# LKS32MC07x register map
Vendor: Linko Ltd.; Series: LKS32MC07x; File version: 1.0
CPU: CM0 r1p0, little endian, MPU, no FPU, 3 interrupt priority bits
Registers are 32-bit, read-write, reset 0x0 unless marked. A register's access mark holds for its fields unless they carry their own. Offsets are from the block's base; [hi:lo] are bit positions; {n}, {i} and the like mark numbered series.

## CAN0 — CAN0 registers
Base 0x40011300
{0x0+4i} RBUF{i} ro (i=0..3) — Receive Buffer register
  [31:0] RDATA — CAN frame date from Rx Buffer Slot
{0x50+4i} TBUF{i} wo (i=0..3) — Transmit Buffer register
  [31:0] WDATA — CAN frame ic written into TX Buffer Slot(PTB or STB)
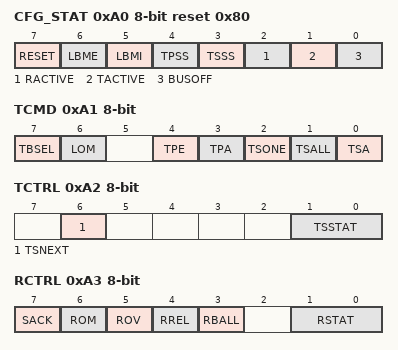
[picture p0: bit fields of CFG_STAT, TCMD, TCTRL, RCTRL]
0xA0 CFG_STAT 8-bit reset 0x80 — Configuration and Status Register
  [7] RESET — RESET request bit
    0=RELEASE (normail mode); 1=RESET (reset mode)
  [6] LBME — Loop Back Mode, External
    0=DISABLED (disable external loop back mode); 1=ENABLED (enable external loop back mode)
  [5] LBMI — Loop Back Mode, Internal
    0=DISABLED (disable internal loop back mode); 1=ENABLED (enable internal loop back mode)
  [4] TPSS — Transmission Primary Single Shot mode for PTB
    0=DISABLED (disable transmission Primary Single Shot mode for PTB); 1=ENABLED (enable transmission Primary Single Shot mode for PTB)
  [3] TSSS — Transmission Secondary Single Shot mode for STB
    0=DISABLED (disable transmission Primary Single Shot mode for STB); 1=ENABLED (enable transmission Primary Single Shot mode for STB)
  [2] RACTIVE ro — Reception ACTIVE
    0=DISABLED (receive idle,bus idle); 1=ENABLED (device is receiving CAN frame)
  [1] TACTIVE ro — Transmission ACTIVE
    0=DISABLED (transimit idle); 1=ENABLED (device is transimitting CAN frame)
  [0] BUSOFF — Bus Off (Bus Status bit)
    0=DISABLED (device is in bus off); 1=DISABLED (device is not in bus off)
0xA1 TCMD 8-bit — Command Register
  [7] TBSEL — Transmit Buffer Select
    0=PTB; 1=STB
  [6] LOM — Listen Only Mode
    0=DISABLED; 1=ENABLED
  [4] TPE ro — Transmit Primary Enable
    0=DISABLED (disable trigger PTB transmit); 1=ENABLED (trigger PTB transmit)
  [3] TPA ro — Transmit Primary Abort
    0=DISABLED; 1=ENABLED
  [2] TSONE ro — Transmit Secondary ONE frame
    0=DISABLED; 1=ENABLED
  [1] TSALL ro — Transmit Secondary ALL frames
    0=DISABLED; 1=ENABLED
  [0] TSA ro — Transmit Secondary Abort
    0=DISABLED; 1=ENABLED
0xA2 TCTRL 8-bit — Transmit Control Register
  [6] TSNEXT — Transmit buffer Secondary NEXT
  [1:0] TSSTAT — Transmission Secondary STATus bits
    0=EMPTY (STB is empty); 1=LTHF (STB is less than or equal to half full); 2=MTHF (STB is more than half full); 3=FULL (STB is full)
0xA3 RCTRL 8-bit — Receive Control Register
  [7] SACK — Self-ACKnowledge
    0=DISABLED (no self-ACK); 1=ENABLED (self-ACK when LBME=1)
  [6] ROM — Receive buffer Overflow Mode
    0=DISABLED (The oldest message will be overwritten); 1=ENABLED (The new message will not be stored)
  [5] ROV ro — Receive buffer Overflow
    0=NOOVFL (No Overflow); 1=OVFL (Overflow. At least one message is lost)
  [4] RREL — Receive buffer RELease
    0=NORELEASE; 1=RELEASE (Release: The host has read the RB)
  [3] RBALL — Receive Buffer stores ALL data frames
    0=DISABLED (normal operation); 1=ENABLED (RB stores correct data frames as well as data frames with error)
  [1:0] RSTAT ro — Receive buffer Status
    0=EMPTY; 1=NOTEMPTY (not empty and less then almost full); 2=ALMOSTFULL (almost full but not full and no overflow); 3=FULL (full, stays set in case of overflow - for overflow signaling see ROV)
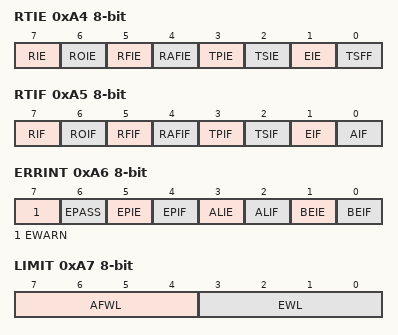
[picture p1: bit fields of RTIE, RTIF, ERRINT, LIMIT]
0xA4 RTIE 8-bit — Receive and Transmit Interrupt Enable Register
  [all] fields
    0=DISABLED; 1=ENABLED
  [7] RIE — Receive Interrupt Enable
  [6] ROIE — RX Buffer Overrun Interrupt Enable
  [5] RFIE — RX Buffer Full Interrupt Interrupt Enable
  [4] RAFIE — RB Almost Full Interrupt Enable
  [3] TPIE — Transmission Primary Interrupt Enable
  [2] TSIE — Transmission Secondary Interrupt Enable
  [1] EIE — Error Interrupt Enable
  [0] TSFF — Tx Buffer Flag
0xA5 RTIF 8-bit — Receive and Transmit Interrupt Flag Register
  [all] fields
    0=CLEAR; 1=SET
  [7] RIF — Receive Interrupt Flag
  [6] ROIF — RB Overrun Interrupt Flag
  [5] RFIF — RB Full Interrupt Flag
  [4] RAFIF — RB Almost Full Interrupt Flag
  [3] TPIF — Transmission Primary Interrupt Flag
  [2] TSIF — Transmission Secondary Interrupt Flag
  [1] EIF — Error Interrupt Flag
  [0] AIF — Abort Interrupt Flag
0xA6 ERRINT 8-bit — Error Interrupt Enable and Flag Register
  [7] EWARN — Error WARNing limit reached
    0=NOTREACH; 1=REACHED
  [6] EPASS ro — Error Passive mode active
    0=ERRACTIVE (CAN is in active error status); 1=ERRPASSIVE (CAN is in passive error status)
  [5] EPIE — Error Passive Interrupt Enable
    0=DISABLED (Error passive interrupt disable); 1=ENABLED (Error passive interrupt enable)
  [4] EPIF — Error Passive Interrupt Flag
    0=CLEAR (clear error passive interrupt flag); 1=SET (detect error passive interrupt flag)
  [3] ALIE — Arbitration Lost Interrupt Enable
    0=DISABLED (Arbitration Lost Interrupt disable); 1=ENABLED (Arbitration Lost Interrupt Enable)
  [2] ALIF — Arbitration Lost Interrupt Flag
    0=CLEAR (clear Arbitration Lost Interrupt Flag); 1=SET (detect Arbitration Lost Interrupt Flag)
  [1] BEIE — Bus Error Interrupt Enable
    0=DISABLED (Bus Error Interrupt disable); 1=ENABLED (Bus Error Interrupt Enable)
  [0] BEIF — Bus Error Interrupt Flag
    0=CLEAR (clear Bus Error Interrupt Flag); 1=SET (detect Bus Error Interrupt Flag)
0xA7 LIMIT 8-bit — Warning Limits Register
  [7:4] AFWL — receive buffer Almost Full Warning Limit
  [3:0] EWL — Programmable Error Warning Limit = (EWL+1)*8
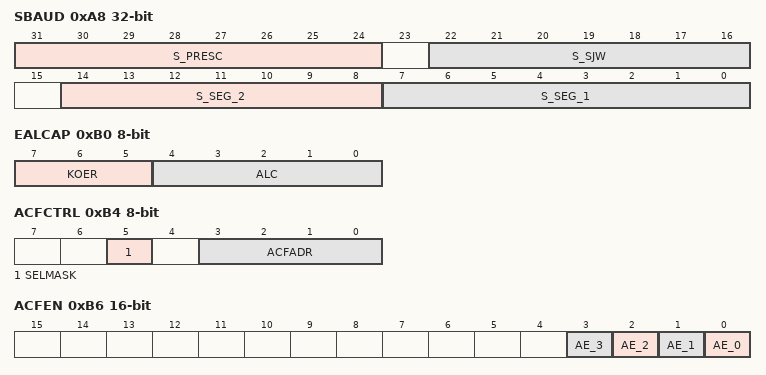
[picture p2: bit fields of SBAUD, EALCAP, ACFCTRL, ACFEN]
0xA8 SBAUD — baud rate configuration register
  [31:24] S_PRESC — Prescaler (slow speed)
  [22:16] S_SJW — Synchronization Jump Width (slow speed)
  [14:8] S_SEG_2 — Bit Timing Segment 2 (slow speed)
  [7:0] S_SEG_1 — Bit Timing Segment 1 (slow speed)
0xB0 EALCAP 8-bit ro — Error and Arbitration Lost Capture Register
  [7:5] KOER — Kind Of Error (Error code)
    0=NOERROR; 1=BITERROR; 2=FORMERROR; 3=STUFFERROR; 4=ACKERROR (ACKNOWLEDGEMENT ERROR); 5=CRCERROR; 6=OTHERERROR
  [4:0] ALC — Arbitration Lost Capture
0xB2 RECNT 8-bit ro — Receive Error Counter Register
  [7:0] RECNT — Receive Error Counter
0xB3 TECNT 8-bit ro — Receive Error Counter Register
  [7:0] TECNT — Teceive Error Counter
0xB4 ACFCTRL 8-bit — Accceptance Filter Control Register
  [5] SELMASK — Select acceptance MASK
    0=SELAMR (Register ACF_x to acceptance code); 1=SELACR (Register ACF_x to acceptance mask)
  [3:0] ACFADR — acceptance filter address
    {v}=ACF_{v} (point into ACF_{v}) (v=0..3)
0xB6 ACFEN 16-bit — Acceptance Filter Enable
  [all] fields
    0=DISABLED; 1=ENABLED
  [n] AE_{n} (n=0..3) — Acceptance Filter {n} Enable
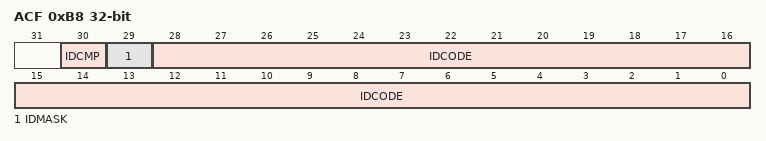
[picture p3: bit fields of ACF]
0xB8 ACF — Acceptance MASK
  [30] IDCMP — ID AMR(MASK)
  [29] IDMASK — MASK format
  [28:0] IDCODE — ID
